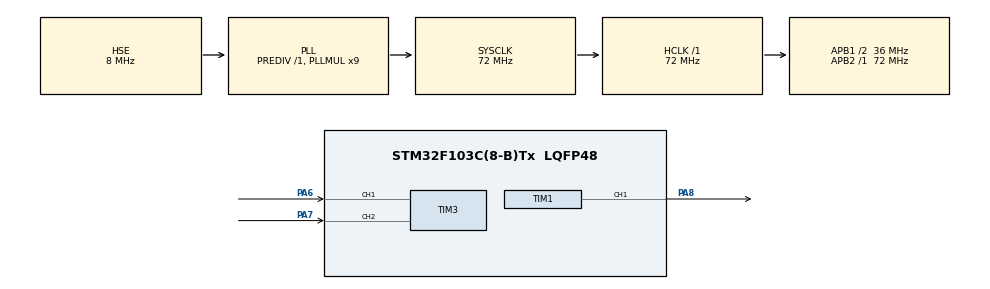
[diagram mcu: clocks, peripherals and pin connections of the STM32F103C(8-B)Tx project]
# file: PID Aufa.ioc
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Mcu.Family=STM32F1
Mcu.Name=STM32F103C(8-B)Tx
Mcu.Package=LQFP48
NVIC.PriorityGroup=NVIC_PRIORITYGROUP_4
NVIC.TIM3_IRQn=true\:0\:0\:false\:false\:true\:true\:true\:true
PA13.Mode=Serial_Wire
PA13.Signal=SYS_JTMS-SWDIO
PA14.Mode=Serial_Wire
PA14.Signal=SYS_JTCK-SWCLK
PA6.GPIO_PuPd=GPIO_PULLUP
PA6.Signal=S_TIM3_CH1
PA7.GPIO_PuPd=GPIO_PULLUP
PA7.Signal=S_TIM3_CH2
PA8.Signal=S_TIM1_CH1
PD0-OSC_IN.Mode=HSE-External-Oscillator
PD0-OSC_IN.Signal=RCC_OSC_IN
PD1-OSC_OUT.Mode=HSE-External-Oscillator
PD1-OSC_OUT.Signal=RCC_OSC_OUT
ProjectManager.HeapSize=0x200
ProjectManager.StackSize=0x400
ProjectManager.TargetToolchain=STM32CubeIDE
RCC.AHBFreq_Value=72000000
RCC.APB1CLKDivider=RCC_HCLK_DIV2
RCC.APB1Freq_Value=36000000
RCC.APB1TimFreq_Value=72000000
RCC.APB2Freq_Value=72000000
RCC.APB2TimFreq_Value=72000000
RCC.HCLKFreq_Value=72000000
RCC.PLLMUL=RCC_PLL_MUL9
RCC.PLLSourceVirtual=RCC_PLLSOURCE_HSE
RCC.SYSCLKFreq_VALUE=72000000
RCC.SYSCLKSource=RCC_SYSCLKSOURCE_PLLCLK
RCC.USBFreq_Value=72000000
SH.S_TIM1_CH1.0=TIM1_CH1,PWM Generation1 CH1
SH.S_TIM3_CH1.0=TIM3_CH1,Encoder_Interface
SH.S_TIM3_CH2.0=TIM3_CH2,Encoder_Interface
TIM1.Channel-PWM\ Generation1\ CH1=TIM_CHANNEL_1
TIM1.Period=20000-1
TIM1.Prescaler=72-1
TIM3.EncoderMode=TIM_ENCODERMODE_TI12
board=custom

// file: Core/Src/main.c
/* USER CODE BEGIN Header */
/**
  ******************************************************************************
  * @file           : main.c
  * @brief          : Main program body
  ******************************************************************************
  * @attention
  *
  * Copyright (c) 2025 STMicroelectronics.
  * All rights reserved.
  *
  * This software is licensed under terms that can be found in the LICENSE file
  * in the root directory of this software component.
  * If no LICENSE file comes with this software, it is provided AS-IS.
  *
  ******************************************************************************
  */
/* USER CODE END Header */
#include "main.h"

/* USER CODE BEGIN PTD */
typedef struct {
    float uk;       // Current control output
    float uk_1;     // Previous control output
    float ek;       // Current error
    float ek_1;     // Previous error
    float ek_2;     // Previous-previous error
} PIDVariables;

PIDVariables pid = {
    .uk = 0.0f,
    .uk_1 = 0.0f,
    .ek = 0.0f,
    .ek_1 = 0.0f,
    .ek_2 = 0.0f
};

/* USER CODE END PTD */

/* USER CODE BEGIN PD */

/* PID gains */
float Kp;
float Ki;
float Kd;

/* PID variables */
float setpoint = 0;
float error = 0;
float integral = 0;
float derivative = 0;
float proportional = 0;

/* Another Variable */
static uint32_t lastTime = 0;
static int32_t lastCount = 0;
int16_t rpm;

int16_t  PPR = 100; /* Adjust the numbers for your encoder */
uint32_t awaktu = 0; /* my custom variable for time sampling */
float sset = 0; /* Custom variable for input setpoint*/

/* USER CODE END PD */

TIM_HandleTypeDef htim1;
TIM_HandleTypeDef htim3;

void SystemClock_Config(void);
static void MX_GPIO_Init(void);
static void MX_TIM1_Init(void);
static void MX_TIM3_Init(void);
/* USER CODE BEGIN PFP */

/* Recursive PID Controller */
void PID_Rekursif(float setpoint, float measure) {

    /* Update error history */
    pid.ek_2 = pid.ek_1;
    pid.ek_1 = pid.ek;

    /*error*/
    pid.ek = setpoint - measure;

    /* Store previous output */
    pid.uk_1 = pid.uk;

    /* Calculate PID terms */
    proportional = Kp * (pid.ek - pid.ek_1);
    integral = Ki * (0.02 / 2.0f) * (pid.ek + pid.ek_1);
    derivative = (Kd / 0.02) * (pid.ek - 2.0f * pid.ek_1 + pid.ek_2);

    /* Calculate new output */
    pid.uk = pid.uk_1 + proportional + integral + derivative;

    /* Apply output limits */
    if (pid.uk > 2000) pid.uk = 2000;
    if (pid.uk < 1000) pid.uk = 1000;

//    return pid.uk;

    /* set PWM duty cycle */
    __HAL_TIM_SET_COMPARE(&htim1, TIM_CHANNEL_1, (uint32_t)pid.uk);
}

/* Conventional PID Controller */
void PID_Konvensional(float setpoint, float measure) {
	float prev_ek = pid.ek;
	float prev_ek_1 = pid.ek_1;

	/* Update error history */
    pid.ek = setpoint - measure;

    pid.ek_2 = prev_ek_1;
    pid.ek_1 = prev_ek;

    /* Store previous output */
    pid.uk_1 = pid.uk;

    /* Calculate PID terms */
    proportional = Kp * pid.ek;
    integral += Ki * pid.ek * 0.02;
    derivative = Kd * (pid.ek - pid.ek_1)/0.02;

    /* Calculate new output */
    pid.uk = proportional + integral + derivative;

    /* Apply output limits */
    if (pid.uk > 2000) pid.uk = 2000;
    if (pid.uk < 1000) pid.uk = 1000;

//    return pid.uk;

    /* set PWM duty cycle */
    __HAL_TIM_SET_COMPARE(&htim1, TIM_CHANNEL_1, (uint32_t)pid.uk);
}

/* Function to calculate motor speed in RPM */
float hitungRPM(){
	    uint32_t currentTime = HAL_GetTick();

	    /* 20 ms sampling time*/
	    if (currentTime - lastTime >= 20) {

	    	/* Encoder Count */
	        int32_t currentCount = (int32_t)__HAL_TIM_GET_COUNTER(&htim3);

	        /* Pulse Count */
	        int32_t deltaPulse = currentCount - lastCount;

	        /* Conditional so it's not negative */
	        if (deltaPulse < 0) {
	            deltaPulse = -deltaPulse;
	        }

	        /* Time Gap */
	        float deltaTime = (float)(currentTime - lastTime) / 1000.0f;

	        /* RPM Convert */
	        rpm = (float)(deltaPulse * 60.0f) / (PPR * deltaTime);

	        /* Update values */
	        lastTime = currentTime;
	        lastCount = currentCount;

	        /* Reset encoder count if out of range */
	        if (currentCount > 60000 || currentCount < -60000) {
	            __HAL_TIM_SET_COUNTER(&htim3, 0);
	            lastCount = 0;
	        }
	    }
	    return rpm;
  }

/* ESC Calibration */
void kalibESC(){
	htim1.Instance->CCR1 = 0;
	HAL_Delay(2000);
	htim1.Instance->CCR1 = 1000;
	HAL_Delay(2000);

}

/*Simple Function for input PWM*/
//void motorAnu(float pwm){
//  	if(pwm>0){
//  		TIM1->CCR1=pwm;
//  	}
//  }

/* USER CODE END PFP */

int main(void)
{

  /* MCU Configuration--------------------------------------------------------*/

  /* Reset of all peripherals, Initializes the Flash interface and the Systick. */
  HAL_Init();

  /* Configure the system clock */
  SystemClock_Config();

  /* Initialize all configured peripherals */
  MX_GPIO_Init();
  MX_TIM1_Init();
  MX_TIM3_Init();
  /* USER CODE BEGIN 2 */

  /* Calibrate ESC and start timers */
  kalibESC();
  HAL_TIM_PWM_Start(&htim1, TIM_CHANNEL_1);
  HAL_TIM_Encoder_Start_IT(&htim3, TIM_CHANNEL_ALL);
//  htim1.Instance->CCR1 = 1000;

  /* USER CODE END 2 */

  /* Infinite loop */
  /* USER CODE BEGIN WHILE */
  while (1)
  {
	  /* Measure RPM */
	  hitungRPM();

	  /* wwaktu for time sampling, update PID every 20 ms */
	  uint32_t wwaktu = HAL_GetTick();
	  	  if (wwaktu - awaktu >= 20) {
				PID_Rekursif(sset, rpm);
				awaktu = wwaktu;
			}

//	  uint32_t wwaktu = HAL_GetTick();
//		  if (wwaktu - awaktu >= 20) {
//				PID_Konvensional(sset, rpm);
//				awaktu = wwaktu;
//			}

    /* USER CODE END WHILE */

  }
}

void SystemClock_Config(void)
{
  RCC_OscInitTypeDef RCC_OscInitStruct = {0};
  RCC_ClkInitTypeDef RCC_ClkInitStruct = {0};

  /** Initializes the RCC Oscillators according to the specified parameters
  * in the RCC_OscInitTypeDef structure.
  */
  RCC_OscInitStruct.OscillatorType = RCC_OSCILLATORTYPE_HSE;
  RCC_OscInitStruct.HSEState = RCC_HSE_ON;
  RCC_OscInitStruct.HSEPredivValue = RCC_HSE_PREDIV_DIV1;
  RCC_OscInitStruct.HSIState = RCC_HSI_ON;
  RCC_OscInitStruct.PLL.PLLState = RCC_PLL_ON;
  RCC_OscInitStruct.PLL.PLLSource = RCC_PLLSOURCE_HSE;
  RCC_OscInitStruct.PLL.PLLMUL = RCC_PLL_MUL9;
  if (HAL_RCC_OscConfig(&RCC_OscInitStruct) != HAL_OK)
  {
    Error_Handler();
  }

  /** Initializes the CPU, AHB and APB buses clocks
  */
  RCC_ClkInitStruct.ClockType = RCC_CLOCKTYPE_HCLK|RCC_CLOCKTYPE_SYSCLK
                              |RCC_CLOCKTYPE_PCLK1|RCC_CLOCKTYPE_PCLK2;
  RCC_ClkInitStruct.SYSCLKSource = RCC_SYSCLKSOURCE_PLLCLK;
  RCC_ClkInitStruct.AHBCLKDivider = RCC_SYSCLK_DIV1;
  RCC_ClkInitStruct.APB1CLKDivider = RCC_HCLK_DIV2;
  RCC_ClkInitStruct.APB2CLKDivider = RCC_HCLK_DIV1;

  if (HAL_RCC_ClockConfig(&RCC_ClkInitStruct, FLASH_LATENCY_2) != HAL_OK)
  {
    Error_Handler();
  }
}

static void MX_TIM1_Init(void)
{

  TIM_MasterConfigTypeDef sMasterConfig = {0};
  TIM_OC_InitTypeDef sConfigOC = {0};
  TIM_BreakDeadTimeConfigTypeDef sBreakDeadTimeConfig = {0};

  htim1.Instance = TIM1;
  htim1.Init.Prescaler = 72-1;
  htim1.Init.CounterMode = TIM_COUNTERMODE_UP;
  htim1.Init.Period = 20000-1;
  htim1.Init.ClockDivision = TIM_CLOCKDIVISION_DIV1;
  htim1.Init.RepetitionCounter = 0;
  htim1.Init.AutoReloadPreload = TIM_AUTORELOAD_PRELOAD_DISABLE;
  if (HAL_TIM_PWM_Init(&htim1) != HAL_OK)
  {
    Error_Handler();
  }
  sMasterConfig.MasterOutputTrigger = TIM_TRGO_RESET;
  sMasterConfig.MasterSlaveMode = TIM_MASTERSLAVEMODE_DISABLE;
  if (HAL_TIMEx_MasterConfigSynchronization(&htim1, &sMasterConfig) != HAL_OK)
  {
    Error_Handler();
  }
  sConfigOC.OCMode = TIM_OCMODE_PWM1;
  sConfigOC.Pulse = 0;
  sConfigOC.OCPolarity = TIM_OCPOLARITY_HIGH;
  sConfigOC.OCNPolarity = TIM_OCNPOLARITY_HIGH;
  sConfigOC.OCFastMode = TIM_OCFAST_DISABLE;
  sConfigOC.OCIdleState = TIM_OCIDLESTATE_RESET;
  sConfigOC.OCNIdleState = TIM_OCNIDLESTATE_RESET;
  if (HAL_TIM_PWM_ConfigChannel(&htim1, &sConfigOC, TIM_CHANNEL_1) != HAL_OK)
  {
    Error_Handler();
  }
  sBreakDeadTimeConfig.OffStateRunMode = TIM_OSSR_DISABLE;
  sBreakDeadTimeConfig.OffStateIDLEMode = TIM_OSSI_DISABLE;
  sBreakDeadTimeConfig.LockLevel = TIM_LOCKLEVEL_OFF;
  sBreakDeadTimeConfig.DeadTime = 0;
  sBreakDeadTimeConfig.BreakState = TIM_BREAK_DISABLE;
  sBreakDeadTimeConfig.BreakPolarity = TIM_BREAKPOLARITY_HIGH;
  sBreakDeadTimeConfig.AutomaticOutput = TIM_AUTOMATICOUTPUT_DISABLE;
  if (HAL_TIMEx_ConfigBreakDeadTime(&htim1, &sBreakDeadTimeConfig) != HAL_OK)
  {
    Error_Handler();
  }
  HAL_TIM_MspPostInit(&htim1);

}

static void MX_TIM3_Init(void)
{

  TIM_Encoder_InitTypeDef sConfig = {0};
  TIM_MasterConfigTypeDef sMasterConfig = {0};

  htim3.Instance = TIM3;
  htim3.Init.Prescaler = 0;
  htim3.Init.CounterMode = TIM_COUNTERMODE_UP;
  htim3.Init.Period = 65535;
  htim3.Init.ClockDivision = TIM_CLOCKDIVISION_DIV1;
  htim3.Init.AutoReloadPreload = TIM_AUTORELOAD_PRELOAD_DISABLE;
  sConfig.EncoderMode = TIM_ENCODERMODE_TI12;
  sConfig.IC1Polarity = TIM_ICPOLARITY_RISING;
  sConfig.IC1Selection = TIM_ICSELECTION_DIRECTTI;
  sConfig.IC1Prescaler = TIM_ICPSC_DIV1;
  sConfig.IC1Filter = 0;
  sConfig.IC2Polarity = TIM_ICPOLARITY_RISING;
  sConfig.IC2Selection = TIM_ICSELECTION_DIRECTTI;
  sConfig.IC2Prescaler = TIM_ICPSC_DIV1;
  sConfig.IC2Filter = 0;
  if (HAL_TIM_Encoder_Init(&htim3, &sConfig) != HAL_OK)
  {
    Error_Handler();
  }
  sMasterConfig.MasterOutputTrigger = TIM_TRGO_RESET;
  sMasterConfig.MasterSlaveMode = TIM_MASTERSLAVEMODE_DISABLE;
  if (HAL_TIMEx_MasterConfigSynchronization(&htim3, &sMasterConfig) != HAL_OK)
  {
    Error_Handler();
  }

}

static void MX_GPIO_Init(void)
{

  /* GPIO Ports Clock Enable */
  __HAL_RCC_GPIOD_CLK_ENABLE();
  __HAL_RCC_GPIOA_CLK_ENABLE();

}

void Error_Handler(void)
{
  __disable_irq();
  while (1)
  {
  }
}
